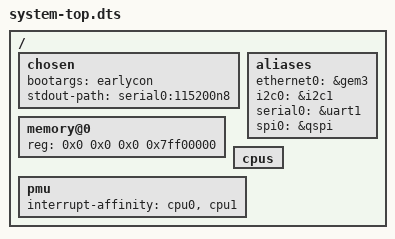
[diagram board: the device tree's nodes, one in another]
/*
 * CAUTION: This file is automatically generated by Xilinx.
 * Version: XSCT 
 * Today is: Mon Oct 26 20:30:49 2026
 */


/dts-v1/;
#include "zynqmp.dtsi"
#include "zynqmp-clk-ccf.dtsi"
#include "pl.dtsi"
#include "pcw.dtsi"
/ {
	chosen {
		bootargs = "earlycon";
		stdout-path = "serial0:115200n8";
	};
	aliases {
		ethernet0 = &gem3;
		i2c0 = &i2c1;
		serial0 = &uart1;
		spi0 = &qspi;
	};
	memory@0 {
		device_type = "memory";
		reg = <0x0 0x0 0x0 0x7ff00000>;
	};
	cpus {
		/delete-node/ cpu@2 ;
		/delete-node/ cpu@3 ;
	};
	pmu {
		interrupt-affinity = <&cpu0>, <&cpu1>;
	};
};
#include "system-user.dtsi"
